# STM32WBxxx_CM4 register map
File version: 1.5
CPU: CM4 r0p1, little endian, MPU, FPU, 4 interrupt priority bits
Registers are 32-bit, read-write, reset 0x0 unless marked. A register's access mark holds for its fields unless they carry their own. Offsets are from the block's base; [hi:lo] are bit positions; 'fields as' and 'values as' point back to an identical list.

## SPI1 — Serial peripheral interface/Inter-IC sound
Base 0x40013000
Same registers: SPI2 0x40003800
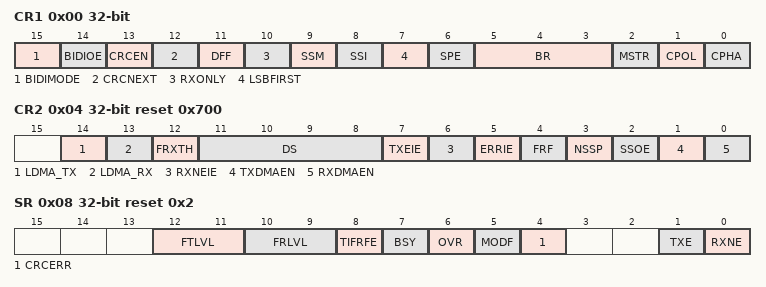
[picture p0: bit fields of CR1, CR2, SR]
0x00 CR1 — control register 1
  [15] BIDIMODE — Bidirectional data mode enable
  [14] BIDIOE — Output enable in bidirectional mode
  [13] CRCEN — Hardware CRC calculation enable
  [12] CRCNEXT — CRC transfer next
  [11] DFF — Data frame format
  [10] RXONLY — Receive only
  [9] SSM — Software slave management
  [8] SSI — Internal slave select
  [7] LSBFIRST — Frame format
  [6] SPE — SPI enable
  [5:3] BR — Baud rate control
  [2] MSTR — Master selection
  [1] CPOL — Clock polarity
  [0] CPHA — Clock phase
0x04 CR2 reset 0x700 — control register 2
  [14] LDMA_TX — Last DMA transfer for transmission
  [13] LDMA_RX — Last DMA transfer for reception
  [12] FRXTH — FIFO reception threshold
  [11:8] DS — Data size
  [7] TXEIE — Tx buffer empty interrupt enable
  [6] RXNEIE — RX buffer not empty interrupt enable
  [5] ERRIE — Error interrupt enable
  [4] FRF — Frame format
  [3] NSSP — NSS pulse management
  [2] SSOE — SS output enable
  [1] TXDMAEN — Tx buffer DMA enable
  [0] RXDMAEN — Rx buffer DMA enable
0x08 SR access per field reset 0x2 — status register
  [12:11] FTLVL ro — FIFO transmission level
  [10:9] FRLVL ro — FIFO reception level
  [8] TIFRFE ro — TI frame format error
  [7] BSY ro — Busy flag
  [6] OVR ro — Overrun flag
  [5] MODF ro — Mode fault
  [4] CRCERR rw — CRC error flag
  [1] TXE ro — Transmit buffer empty
  [0] RXNE ro — Receive buffer not empty
0x0C DR — data register
  [15:0] DR — Data register
0x10 CRCPR reset 0x7 — CRC polynomial register
  [15:0] CRCPOLY
0x14 RXCRCR ro — RX CRC register
  [15:0] RxCRC
0x18 TXCRCR ro — TX CRC register
  [15:0] TxCRC

## VREFBUF — Voltage reference buffer
Base 0x40010030
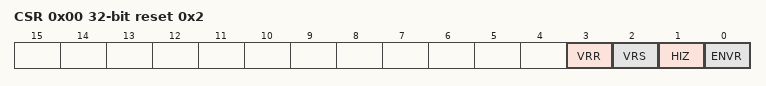
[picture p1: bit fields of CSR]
0x00 CSR access per field reset 0x2 — VREF control and status register
  [3] VRR ro — Voltage reference buffer ready
  [2] VRS rw — Voltage reference scale
  [1] HIZ rw — High impedance mode
  [0] ENVR rw — Voltage reference buffer enable
0x04 CCR — calibration control register
  [5:0] TRIM — Trimming code

## DBGMCU — Debug support
Base 0xE0042000
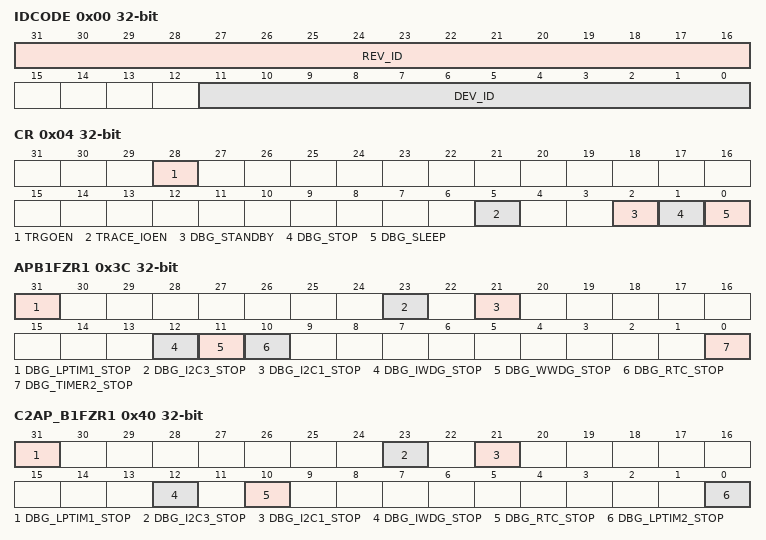
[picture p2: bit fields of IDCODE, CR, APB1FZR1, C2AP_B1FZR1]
0x00 IDCODE ro — MCU Device ID Code Register
  [31:16] REV_ID — Revision Identifier
  [11:0] DEV_ID — Device Identifier
0x04 CR — Debug MCU Configuration Register
  [28] TRGOEN — External trigger output enable
  [5] TRACE_IOEN — Trace port and clock enable
  [2] DBG_STANDBY — Debug Standby Mode
  [1] DBG_STOP — Debug Stop Mode
  [0] DBG_SLEEP — Debug Sleep Mode
0x3C APB1FZR1 — APB1 Low Freeze Register CPU1
  [31] DBG_LPTIM1_STOP — Debug LPTIM1 stopped when Core is halted
  [23] DBG_I2C3_STOP — Debug I2C3 SMBUS timeout stopped when core is halted
  [21] DBG_I2C1_STOP — Debug I2C1 SMBUS timeout stopped when Core is halted
  [12] DBG_IWDG_STOP — IWDG counter stopped when core is halted
  [11] DBG_WWDG_STOP — WWDG counter stopped when core is halted
  [10] DBG_RTC_STOP — RTC counter stopped when core is halted
  [0] DBG_TIMER2_STOP — Debug Timer 2 stopped when Core is halted
0x40 C2AP_B1FZR1 — APB1 Low Freeze Register CPU2
  [31] DBG_LPTIM1_STOP — LPTIM1 counter stopped when core is halted
  [23] DBG_I2C3_STOP — I2C3 SMBUS timeout stopped when core is halted
  [21] DBG_I2C1_STOP — I2C1 SMBUS timeout stopped when core is halted
  [12] DBG_IWDG_STOP — IWDG stopped when core is halted
  [10] DBG_RTC_STOP — RTC counter stopped when core is halted
  [0] DBG_LPTIM2_STOP — LPTIM2 counter stopped when core is halted
0x44 APB1FZR2 — APB1 High Freeze Register CPU1
  [5] DBG_LPTIM2_STOP — LPTIM2 counter stopped when core is halted
0x48 C2APB1FZR2 — APB1 High Freeze Register CPU2
  [5] DBG_LPTIM2_STOP — LPTIM2 counter stopped when core is halted
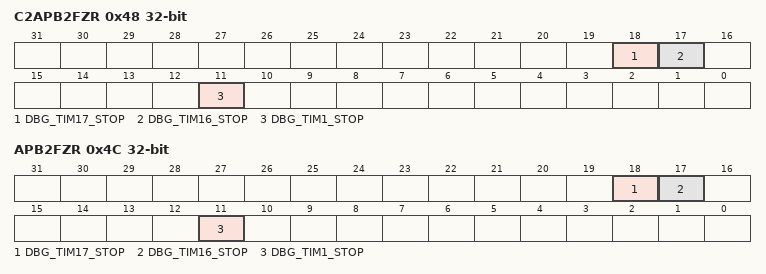
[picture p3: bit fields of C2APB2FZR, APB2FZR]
0x48 C2APB2FZR (alternate view of C2APB1FZR2) — APB2 Freeze Register CPU2
  [18] DBG_TIM17_STOP — TIM17 counter stopped when core is halted
  [17] DBG_TIM16_STOP — TIM16 counter stopped when core is halted
  [11] DBG_TIM1_STOP — TIM1 counter stopped when core is halted
0x4C APB2FZR — APB2 Freeze Register CPU1
  fields as C2APB2FZR
